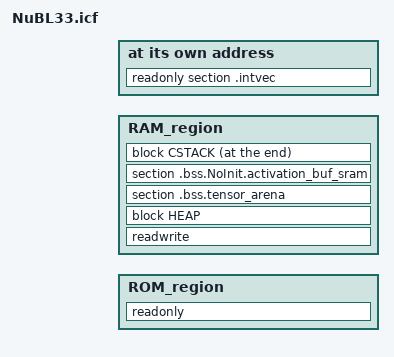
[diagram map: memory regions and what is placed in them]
/*###ICF### Section handled by ICF editor, don't touch! ****/
/*-Editor annotation file-*/
/* IcfEditorFile="$TOOLKIT_DIR$\config\ide\IcfEditor\cortex_v1_0.xml" */
/*-Specials-*/
define symbol __ICFEDIT_intvec_start__ = (0x10100000 + 0x80000 + 0x800);	/* 0x800 is secure image header size */

/*-Memory Regions-*/
define symbol __ICFEDIT_region_ROM_start__  = (0x10100000 + 0x80000 + 0x800);	/* 0x800 is secure image header size */
define symbol __ICFEDIT_region_ROM_end__    = (__ICFEDIT_region_ROM_start__ + 0x180000 - 1);

define symbol __ICFEDIT_region_RAM_start__  = (0x30100000 + 0x100000);
define symbol __ICFEDIT_region_RAM_end__    = (__ICFEDIT_region_RAM_start__ + 0x50000 - 1);

/*-Sizes-*/
define symbol __ICFEDIT_size_cstack__ = 0x00000800;
define symbol __ICFEDIT_size_heap__   = 0x00000800;
/**** End of ICF editor section. ###ICF###*/

define memory mem with size = 4G;
define region ROM_region  = mem:[from __ICFEDIT_region_ROM_start__  to __ICFEDIT_region_ROM_end__ ];
define region RAM_region  = mem:[from __ICFEDIT_region_RAM_start__  to __ICFEDIT_region_RAM_end__ ];

define block CSTACK with alignment = 8, size = __ICFEDIT_size_cstack__ { };
define block HEAP   with alignment = 8, size = __ICFEDIT_size_heap__   { };

initialize by copy { readwrite, section DTCM.VTOR, section ITCM, section DTCM.Init };

do not initialize  { section .noinit, section .bss.tensor_arena, section .bss.NoInit.activation_buf_sram };

place at address mem:__ICFEDIT_intvec_start__ { readonly section .intvec };

place in ROM_region  { readonly };
place in RAM_region  { readwrite, block HEAP, section .bss.tensor_arena, section .bss.NoInit.activation_buf_sram };
place at end of RAM_region { block CSTACK };
